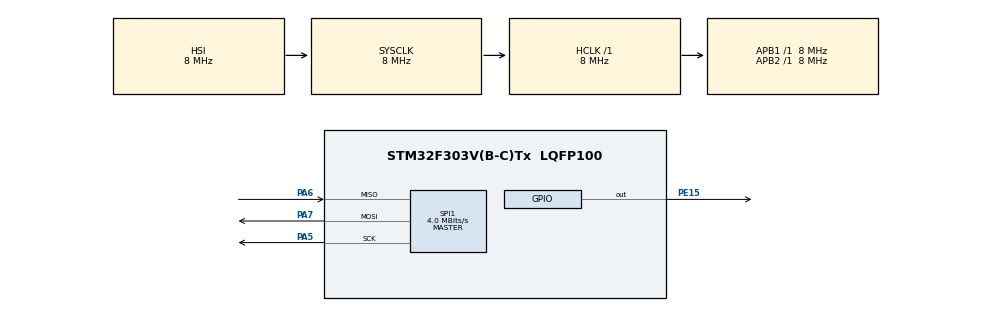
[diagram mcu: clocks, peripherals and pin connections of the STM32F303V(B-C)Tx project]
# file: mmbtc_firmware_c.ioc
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FREERTOS.Tasks01=defaultTask,24,128,StartDefaultTask,Default,NULL,Dynamic,NULL,NULL
FREERTOS.configUSE_NEWLIB_REENTRANT=1
Mcu.Family=STM32F3
Mcu.Name=STM32F303V(B-C)Tx
Mcu.Package=LQFP100
NVIC.PriorityGroup=NVIC_PRIORITYGROUP_4
NVIC.TIM6_DAC_IRQn=true\:15\:0\:false\:false\:true\:false\:false\:true
NVIC.TimeBase=TIM6_DAC_IRQn
NVIC.TimeBaseIP=TIM6
PA5.Mode=Full_Duplex_Master
PA5.Signal=SPI1_SCK
PA6.Mode=Full_Duplex_Master
PA6.Signal=SPI1_MISO
PA7.Mode=Full_Duplex_Master
PA7.Signal=SPI1_MOSI
PE15.Signal=GPIO_Output
ProjectManager.HeapSize=0x200
ProjectManager.StackSize=0x400
ProjectManager.TargetToolchain=STM32CubeIDE
RCC.AHBFreq_Value=8000000
RCC.APB1Freq_Value=8000000
RCC.APB2Freq_Value=8000000
RCC.CortexFreq_Value=8000000
RCC.HSE_VALUE=8000000
RCC.HSI_VALUE=8000000
RCC.LSE_VALUE=32768
RCC.SYSCLKFreq_VALUE=8000000
SPI1.CalculateBaudRate=4.0 MBits/s
SPI1.Direction=SPI_DIRECTION_2LINES
SPI1.Mode=SPI_MODE_MASTER
SPI1.VirtualType=VM_MASTER
VP_CRC_VS_CRC.Mode=CRC_Activate
VP_FREERTOS_VS_CMSIS_V2.Mode=CMSIS_V2
VP_RTC_VS_RTC_Activate.Mode=RTC_Enabled
VP_SYS_VS_tim6.Mode=TIM6
board=custom

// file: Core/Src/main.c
/* USER CODE BEGIN Header */
/**
  ******************************************************************************
  * @file           : main.c
  * @brief          : Main program body
  ******************************************************************************
  * @attention
  *
  * Copyright (c) 2022 STMicroelectronics.
  * All rights reserved.
  *
  * This software is licensed under terms that can be found in the LICENSE file
  * in the root directory of this software component.
  * If no LICENSE file comes with this software, it is provided AS-IS.
  *
  ******************************************************************************
  */
/* USER CODE END Header */
#include "main.h"
#include "cmsis_os.h"

/* USER CODE BEGIN Includes */
#include "bip39.h"
// #include "interface_w_c.h"
/* USER CODE END Includes */

CRC_HandleTypeDef hcrc;

RTC_HandleTypeDef hrtc;

SPI_HandleTypeDef hspi1;

static volatile char *s;

/* Definitions for defaultTask */
osThreadId_t defaultTaskHandle;
const osThreadAttr_t defaultTask_attributes = {
    .name = "defaultTask",
    .stack_size = 128 * 4,
    .priority = (osPriority_t)osPriorityNormal,
};

void SystemClock_Config(void);
static void MX_GPIO_Init(void);
static void MX_CRC_Init(void);
static void MX_RTC_Init(void);
static void MX_SPI1_Init(void);
void StartDefaultTask(void *argument);

int main(void)
{

  /* MCU Configuration--------------------------------------------------------*/

  /* Reset of all peripherals, Initializes the Flash interface and the Systick. */
  HAL_Init();

  /* Configure the system clock */
  SystemClock_Config();

  /* Initialize all configured peripherals */
  MX_GPIO_Init();
  MX_CRC_Init();
  MX_RTC_Init();
  MX_SPI1_Init();

  /* Init scheduler */
  osKernelInitialize();

  /* Create the thread(s) */
  /* creation of defaultTask */
  defaultTaskHandle = osThreadNew(StartDefaultTask, NULL, &defaultTask_attributes);

  /* Start scheduler */
  osKernelStart();

  /* We should never get here as control is now taken by the scheduler */
  /* Infinite loop */
  while (1)
  {

  }
}

void SystemClock_Config(void)
{
  RCC_OscInitTypeDef RCC_OscInitStruct = {0};
  RCC_ClkInitTypeDef RCC_ClkInitStruct = {0};
  RCC_PeriphCLKInitTypeDef PeriphClkInit = {0};

  /** Initializes the RCC Oscillators according to the specified parameters
  * in the RCC_OscInitTypeDef structure.
  */
  RCC_OscInitStruct.OscillatorType = RCC_OSCILLATORTYPE_HSI | RCC_OSCILLATORTYPE_LSI;
  RCC_OscInitStruct.HSIState = RCC_HSI_ON;
  RCC_OscInitStruct.HSICalibrationValue = RCC_HSICALIBRATION_DEFAULT;
  RCC_OscInitStruct.LSIState = RCC_LSI_ON;
  RCC_OscInitStruct.PLL.PLLState = RCC_PLL_NONE;
  if (HAL_RCC_OscConfig(&RCC_OscInitStruct) != HAL_OK)
  {
    Error_Handler();
  }
  /** Initializes the CPU, AHB and APB buses clocks
  */
  RCC_ClkInitStruct.ClockType = RCC_CLOCKTYPE_HCLK | RCC_CLOCKTYPE_SYSCLK | RCC_CLOCKTYPE_PCLK1 | RCC_CLOCKTYPE_PCLK2;
  RCC_ClkInitStruct.SYSCLKSource = RCC_SYSCLKSOURCE_HSI;
  RCC_ClkInitStruct.AHBCLKDivider = RCC_SYSCLK_DIV1;
  RCC_ClkInitStruct.APB1CLKDivider = RCC_HCLK_DIV1;
  RCC_ClkInitStruct.APB2CLKDivider = RCC_HCLK_DIV1;

  if (HAL_RCC_ClockConfig(&RCC_ClkInitStruct, FLASH_LATENCY_0) != HAL_OK)
  {
    Error_Handler();
  }
  PeriphClkInit.PeriphClockSelection = RCC_PERIPHCLK_RTC;
  PeriphClkInit.RTCClockSelection = RCC_RTCCLKSOURCE_LSI;
  if (HAL_RCCEx_PeriphCLKConfig(&PeriphClkInit) != HAL_OK)
  {
    Error_Handler();
  }
}

static void MX_CRC_Init(void)
{

  hcrc.Instance = CRC;
  hcrc.Init.DefaultPolynomialUse = DEFAULT_POLYNOMIAL_ENABLE;
  hcrc.Init.DefaultInitValueUse = DEFAULT_INIT_VALUE_ENABLE;
  hcrc.Init.InputDataInversionMode = CRC_INPUTDATA_INVERSION_NONE;
  hcrc.Init.OutputDataInversionMode = CRC_OUTPUTDATA_INVERSION_DISABLE;
  hcrc.InputDataFormat = CRC_INPUTDATA_FORMAT_BYTES;
  if (HAL_CRC_Init(&hcrc) != HAL_OK)
  {
    Error_Handler();
  }
}

static void MX_RTC_Init(void)
{

  /** Initialize RTC Only
  */
  hrtc.Instance = RTC;
  hrtc.Init.HourFormat = RTC_HOURFORMAT_24;
  hrtc.Init.AsynchPrediv = 127;
  hrtc.Init.SynchPrediv = 255;
  hrtc.Init.OutPut = RTC_OUTPUT_DISABLE;
  hrtc.Init.OutPutPolarity = RTC_OUTPUT_POLARITY_HIGH;
  hrtc.Init.OutPutType = RTC_OUTPUT_TYPE_OPENDRAIN;
  if (HAL_RTC_Init(&hrtc) != HAL_OK)
  {
    Error_Handler();
  }
}

static void MX_SPI1_Init(void)
{

  /* SPI1 parameter configuration*/
  hspi1.Instance = SPI1;
  hspi1.Init.Mode = SPI_MODE_MASTER;
  hspi1.Init.Direction = SPI_DIRECTION_2LINES;
  hspi1.Init.DataSize = SPI_DATASIZE_4BIT;
  hspi1.Init.CLKPolarity = SPI_POLARITY_LOW;
  hspi1.Init.CLKPhase = SPI_PHASE_1EDGE;
  hspi1.Init.NSS = SPI_NSS_SOFT;
  hspi1.Init.BaudRatePrescaler = SPI_BAUDRATEPRESCALER_2;
  hspi1.Init.FirstBit = SPI_FIRSTBIT_MSB;
  hspi1.Init.TIMode = SPI_TIMODE_DISABLE;
  hspi1.Init.CRCCalculation = SPI_CRCCALCULATION_DISABLE;
  hspi1.Init.CRCPolynomial = 7;
  hspi1.Init.CRCLength = SPI_CRC_LENGTH_DATASIZE;
  hspi1.Init.NSSPMode = SPI_NSS_PULSE_ENABLE;
  if (HAL_SPI_Init(&hspi1) != HAL_OK)
  {
    Error_Handler();
  }
}

static void MX_GPIO_Init(void)
{
  GPIO_InitTypeDef GPIO_InitStruct = {0};

  /* GPIO Ports Clock Enable */
  __HAL_RCC_GPIOA_CLK_ENABLE();
  __HAL_RCC_GPIOE_CLK_ENABLE();

  /*Configure GPIO pin Output Level */
  HAL_GPIO_WritePin(GPIOE, GPIO_PIN_15, GPIO_PIN_RESET);

  /*Configure GPIO pin : PE15 */
  GPIO_InitStruct.Pin = GPIO_PIN_15;
  GPIO_InitStruct.Mode = GPIO_MODE_OUTPUT_PP;
  GPIO_InitStruct.Pull = GPIO_NOPULL;
  GPIO_InitStruct.Speed = GPIO_SPEED_FREQ_LOW;
  HAL_GPIO_Init(GPIOE, &GPIO_InitStruct);
}

void StartDefaultTask(void *argument)
{
  /* USER CODE BEGIN 5 */
  /* Infinite loop */
  for (;;)
  {
    HAL_GPIO_TogglePin(GPIOE, GPIO_PIN_15);
    osDelay(500);

    s = mnemonic_generate(256);
  }
  /* USER CODE END 5 */
}

void HAL_TIM_PeriodElapsedCallback(TIM_HandleTypeDef *htim)
{
  if (htim->Instance == TIM6)
  {
    HAL_IncTick();
  }
}

void Error_Handler(void)
{
  __disable_irq();
  while (1)
  {
  }
}
